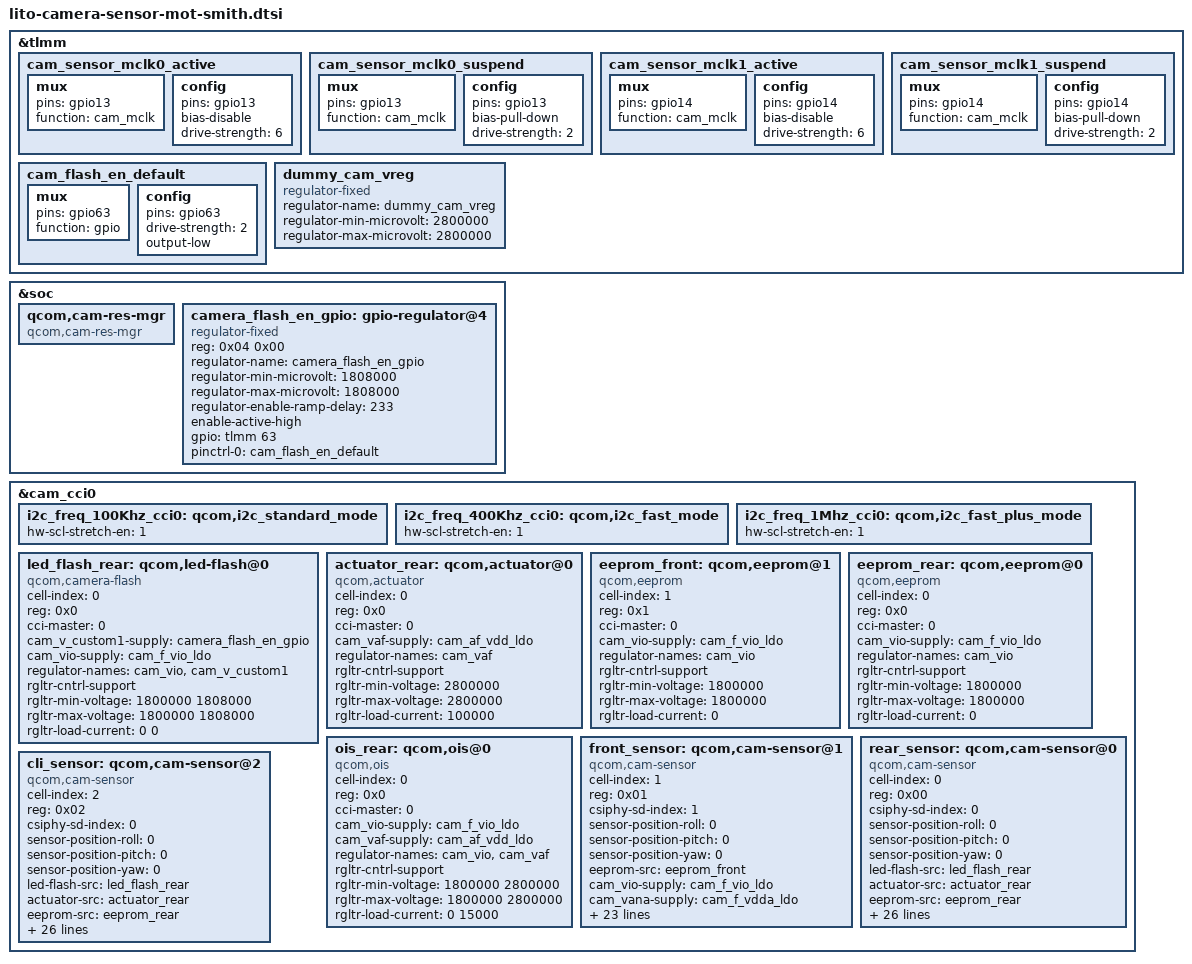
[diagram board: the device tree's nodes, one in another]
#include <dt-bindings/clock/qcom,camcc-lito.h>

&tlmm {
	cam_sensor_mclk0_active: cam_sensor_mclk0_active{
		/* MCLK0 */
		mux {
			pins = "gpio13";
			function = "cam_mclk";
		};

		config {
			pins = "gpio13";
			bias-disable; /* No PULL */
			drive-strength = <6>; /* 6 MA */
		};
	};

	cam_sensor_mclk0_suspend: cam_sensor_mclk0_suspend {
		/* MCLK0 */
		mux {
			pins = "gpio13";
			function = "cam_mclk";
		};

		config {
			pins = "gpio13";
			bias-pull-down; /* PULL DOWN */
			drive-strength = <2>; /* 2 MA */
		};
	};

	cam_sensor_mclk1_active: cam_sensor_mclk1_active {
		/* MCLK1 */
		mux {
			pins = "gpio14";
			function = "cam_mclk";
		};

		config {
			pins = "gpio14";
			bias-disable; /* No PULL */
			drive-strength = <6>; /* 6 MA */
		};
	};

	cam_sensor_mclk1_suspend: cam_sensor_mclk1_suspend {
		/* MCLK1 */
		mux {
			pins = "gpio14";
			function = "cam_mclk";
		};

		config {
			pins = "gpio14";
			bias-pull-down; /* PULL DOWN */
			drive-strength = <2>; /* 2 MA */
		};
	};

	cam_flash_en_default: cam_flash_en_default {
		/* RESET */
		mux {
			pins = "gpio63";
			function = "gpio";
		};

		config{
			pins = "gpio63";
			drive-strength = <2>; /* 2 MA */
			output-low;
		};
	};

	dummy_cam_vreg: dummy_cam_vreg {
		compatible = "regulator-fixed";
		status = "ok";
		regulator-name = "dummy_cam_vreg";
		regulator-min-microvolt = <2800000>;
		regulator-max-microvolt = <2800000>;
	};
};

&soc {
	qcom,cam-res-mgr {
		compatible = "qcom,cam-res-mgr";
		status = "ok";
	};

	camera_flash_en_gpio: gpio-regulator@4{
		compatible = "regulator-fixed";
		reg = <0x04 0x00>;
		regulator-name = "camera_flash_en_gpio";
		regulator-min-microvolt = <1808000>;
		regulator-max-microvolt = <1808000>;
		regulator-enable-ramp-delay = <233>;
		enable-active-high;
		gpio = <&tlmm 63 0>;
		pinctrl-names = "default";
		pinctrl-0 = <&cam_flash_en_default>;
	};
};

&cam_cci0 {
	i2c_freq_100Khz_cci0: qcom,i2c_standard_mode {
		hw-scl-stretch-en = <1>;
	};

	i2c_freq_400Khz_cci0: qcom,i2c_fast_mode {
		hw-scl-stretch-en = <1>;
	};

	i2c_freq_1Mhz_cci0: qcom,i2c_fast_plus_mode {
		hw-scl-stretch-en = <1>;
	};

	led_flash_rear: qcom,led-flash@0{
		cell-index = <0>;
		reg = <0x0>;
		compatible = "qcom,camera-flash";
		cci-master = <0>;
		cam_v_custom1-supply = <&camera_flash_en_gpio>;
		cam_vio-supply = <&cam_f_vio_ldo>;
		regulator-names = "cam_vio", "cam_v_custom1";
		rgltr-cntrl-support;
		rgltr-min-voltage = <1800000 1808000>;
		rgltr-max-voltage = <1800000 1808000>;
		rgltr-load-current = <0 0>;
		status = "ok";
	};

	actuator_rear: qcom,actuator@0 {
		cell-index = <0>;
		reg = <0x0>;
		compatible = "qcom,actuator";
		cci-master = <0>;
		cam_vaf-supply = <&cam_af_vdd_ldo>;
		regulator-names = "cam_vaf";
		rgltr-cntrl-support;
		rgltr-min-voltage = <2800000>;
		rgltr-max-voltage = <2800000>;
		rgltr-load-current = <100000>;
		status = "ok";
	};

	eeprom_front: qcom,eeprom@1 {
		cell-index = <1>;
		reg = <0x1>;
		compatible = "qcom,eeprom";
		cci-master = <0>;
		cam_vio-supply = <&cam_f_vio_ldo>;
		regulator-names = "cam_vio";
		rgltr-cntrl-support;
		rgltr-min-voltage = <1800000>;
		rgltr-max-voltage = <1800000>;
		rgltr-load-current = <0>;
		status = "ok";
	};

	eeprom_rear: qcom,eeprom@0 {
		cell-index = <0>;
		reg = <0x0>;
		compatible = "qcom,eeprom";
		cci-master = <0>;
		cam_vio-supply = <&cam_f_vio_ldo>;
		regulator-names = "cam_vio";
		rgltr-cntrl-support;
		rgltr-min-voltage = <1800000>;
		rgltr-max-voltage = <1800000>;
		rgltr-load-current = <0>;
		status = "ok";
	};

	ois_rear: qcom,ois@0 {
		cell-index = <0>;
		reg = <0x0>;
		compatible = "qcom,ois";
		cci-master = <0>;
		cam_vio-supply = <&cam_f_vio_ldo>;
		cam_vaf-supply = <&cam_af_vdd_ldo>;
		regulator-names = "cam_vio", "cam_vaf";
		rgltr-cntrl-support;
		rgltr-min-voltage = <1800000 2800000>;
		rgltr-max-voltage = <1800000 2800000>;
		rgltr-load-current = <0 15000>;
		status = "ok";
	};

	front_sensor: qcom,cam-sensor@1 {
		cell-index = <1>;
		compatible = "qcom,cam-sensor";
		reg = <0x01>;
		csiphy-sd-index = <1>; /* MIPI index of the CSIPHY bus, refere schematic for the location */
		sensor-position-roll = <0>;
		sensor-position-pitch = <0>;
		sensor-position-yaw = <0>;
		eeprom-src = <&eeprom_front>;
		cam_vio-supply = <&cam_f_vio_ldo>;
		cam_vana-supply = <&cam_f_vdda_ldo>;
		cam_vdig-supply = <&cam_f_vddd_ldo>;
		cam_clk-supply = <&titan_top_gdsc>;
		regulator-names = "cam_vio", "cam_vana", "cam_vdig", "cam_clk";
		rgltr-cntrl-support;
		rgltr-min-voltage = <1800000 2800000 1050000 0>;
		rgltr-max-voltage = <1800000 2800000 1050000 0>;
		rgltr-load-current = < 1000 60000 200000 0>;
		gpio-no-mux = <0>;
		pinctrl-names = "cam_default", "cam_suspend";
		pinctrl-0 = <&cam_sensor_mclk0_active
					&cam_sensor_active_front>;
		pinctrl-1 = <&cam_sensor_mclk0_suspend
					&cam_sensor_suspend_front>;
		gpios = <&tlmm 13 0>,
			<&tlmm 32 0>;
		gpio-reset = <1>;
		gpio-req-tbl-num = <0 1>;
		gpio-req-tbl-flags = <1 0>;
		gpio-req-tbl-label = "CAMIF_MCLK0",
				"CAM_RESET0";
		sensor-mode = <0>;
		cci-master = <0>;
		status = "ok";
		clocks = <&camcc CAM_CC_MCLK0_CLK>;
		clock-names = "cam_clk";
		clock-cntl-level = "turbo";
		clock-rates = <24000000>;
	};

	rear_sensor: qcom,cam-sensor@0 {
		cell-index = <0>;
		compatible = "qcom,cam-sensor";
		reg = <0x00>;
		csiphy-sd-index = <0>; /* MIPI index of the CSIPHY bus, refere schematic for the location */
		sensor-position-roll = <0>;
		sensor-position-pitch = <0>;
		sensor-position-yaw = <0>;
		led-flash-src = <&led_flash_rear>;
		actuator-src = <&actuator_rear>;
		eeprom-src = <&eeprom_rear>;
		ois-src = <&ois_rear>;
		cam_vio-supply = <&cam_f_vio_ldo>;
		cam_vana-supply = <&cam_r_vdda_ldo>;
		cam_vdig-supply = <&cam_r_vddd_ldo>;
		cam_clk-supply = <&titan_top_gdsc>;
		regulator-names = "cam_vio", "cam_vana", "cam_vdig", "cam_clk";
		rgltr-cntrl-support;
		rgltr-min-voltage = <1800000 2800000 1050000 0>;
		rgltr-max-voltage = <1800000 2800000 1050000 0>;
		rgltr-load-current = < 1000 55000 190000 0>;   /* This value is obtained from the Sensor datasheet supply current under streaming mode */
		gpio-no-mux = <0>;
		pinctrl-names = "cam_default", "cam_suspend";
		pinctrl-0 = <&cam_sensor_mclk1_active
					&cam_sensor_active_rear>;
		pinctrl-1 = <&cam_sensor_mclk1_suspend
					&cam_sensor_suspend_rear>;
		gpios = <&tlmm 14 0>,
			<&tlmm 30 0>;
		gpio-reset = <1>;
		gpio-req-tbl-num = <0 1>;
		gpio-req-tbl-flags = <1 0>;
		gpio-req-tbl-label = "CAMIF_MCLK1",
				"CAM_RESET1";
		sensor-mode = <0>;
		cci-master = <0>;
		status = "ok";
		clocks = <&camcc CAM_CC_MCLK1_CLK>;
		clock-names = "cam_clk";
		clock-cntl-level = "turbo";
		clock-rates = <24000000>;
	};

	cli_sensor: qcom,cam-sensor@2 {
		cell-index = <2>;
		compatible = "qcom,cam-sensor";
		reg = <0x02>;
		csiphy-sd-index = <0>; /* MIPI index of the CSIPHY bus, refere schematic for the location */
		sensor-position-roll = <0>;
		sensor-position-pitch = <0>;
		sensor-position-yaw = <0>;
		led-flash-src = <&led_flash_rear>;
		actuator-src = <&actuator_rear>;
		eeprom-src = <&eeprom_rear>;
		ois-src = <&ois_rear>;
		cam_vio-supply = <&cam_f_vio_ldo>;
		cam_vana-supply = <&cam_r_vdda_ldo>;
		cam_vdig-supply = <&cam_r_vddd_ldo>;
		cam_clk-supply = <&titan_top_gdsc>;
		regulator-names = "cam_vio", "cam_vana", "cam_vdig", "cam_clk";
		rgltr-cntrl-support;
		rgltr-min-voltage = <1800000 2800000 1050000 0>;
		rgltr-max-voltage = <1800000 2800000 1050000 0>;
		rgltr-load-current = < 1000 55000 190000 0>;   /* This value is obtained from the Sensor datasheet supply current under streaming mode */
		gpio-no-mux = <0>;
		pinctrl-names = "cam_default", "cam_suspend";
		pinctrl-0 = <&cam_sensor_mclk1_active
					&cam_sensor_active_rear>;
		pinctrl-1 = <&cam_sensor_mclk1_suspend
					&cam_sensor_suspend_rear>;
		gpios = <&tlmm 14 0>,
			<&tlmm 30 0>;
		gpio-reset = <1>;
		gpio-req-tbl-num = <0 1>;
		gpio-req-tbl-flags = <1 0>;
		gpio-req-tbl-label = "CAMIF_MCLK1",
				"CAM_RESET1";
		sensor-mode = <0>;
		cci-master = <0>;
		status = "ok";
		clocks = <&camcc CAM_CC_MCLK1_CLK>;
		clock-names = "cam_clk";
		clock-cntl-level = "turbo";
		clock-rates = <24000000>;
	};
};

